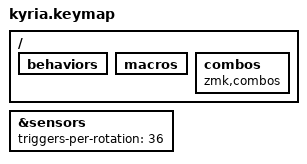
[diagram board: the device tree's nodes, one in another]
/*
 * Copyright (c) 2020 The ZMK Contributors
 *
 * SPDX-License-Identifier: MIT
 */

#include <behaviors.dtsi>
#include <dt-bindings/zmk/keys.h>
#include <dt-bindings/zmk/bt.h>


#include "moutis/moutis_config.dtsi"    // my add-on feature defs

#include "keymaps/keynames_kyria_3x5.h" // key name defs for this board topology
#include "layouts/hd/vf-config.h"       // HD alpha keymap, adapt, and combo definitions

&sensors {
        triggers-per-rotation = <36>;
};

/ {
/*
 * Behaviors
 */
    behaviors {

#include "moutis/moutis_sensors.dtsi"   // EC11 & other sensor behaviors
#include "moutis/moutis_behaviors.dtsi" // common behaviors (hold-taps, mod-morphs, lingers, adaptives)
#include HD_adapt_file                  // HDalpha/mnemonic based adaptives (most of them)

    };

/*
 * Macros
 */
    macros {
    
#include "moutis/moutis_macros.dtsi"    // common macros (superset)

    };

/*
 * Combos
 */
    combos {
        compatible = "zmk,combos";

#include "moutis/moutis_combos.dtsi"    // common/location based combos (cut/copy/paste, esc, app, etc.)
#include HD_combo_file                  // HD alpha/mnemonic based combos (h-digraphs, etc.)

    };
/*
 * Keymap (all layers w/references to all the above)
 */

#include "keymaps/keymap_kyria_3x5.dtsi"    // consolidated keymap

};
